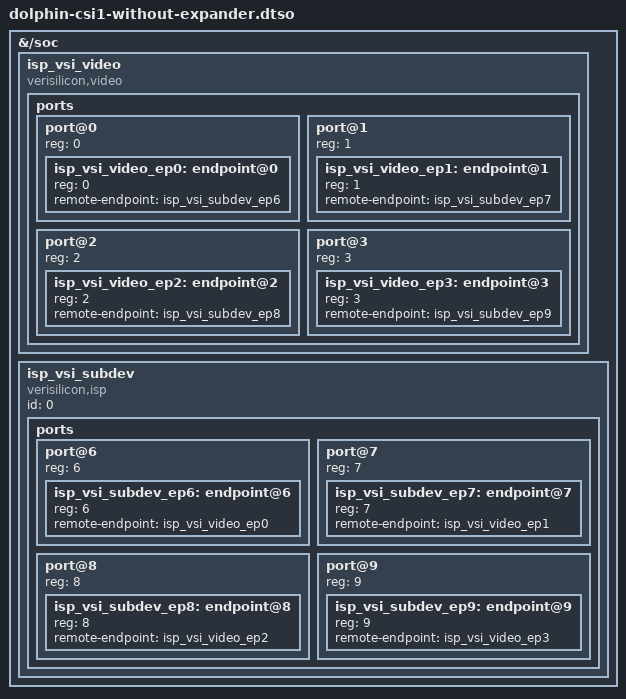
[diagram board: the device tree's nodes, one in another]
#include <dt-bindings/gpio/gpio.h>

/dts-v1/;
/plugin/;


/ {

	fragment@0 {
		target-path = "/soc";
		__overlay__ {
			isp_vsi_video: isp_vsi_video {
				status = "okay";
				compatible = "verisilicon,video";
				ports {
					/delete-property/port@0;
					/delete-property/port@1;
					/delete-property/port@2;
					/delete-property/port@3;
					#address-cells = <1>;
					#size-cells = <0>;
					port@0 {
						reg = <0>;
						#address-cells = <1>;
						#size-cells = <0>;
						isp_vsi_video_ep0: endpoint@0 {
							reg = <0>;
							remote-endpoint = <&isp_vsi_subdev_ep6>;
						};
					};
					port@1 {
						reg = <1>;
						#address-cells = <1>;
						#size-cells = <0>;
						isp_vsi_video_ep1: endpoint@1 {
							reg = <1>;
							remote-endpoint = <&isp_vsi_subdev_ep7>;
						};
					};
					port@2 {
						reg = <2>;
						#address-cells = <1>;
						#size-cells = <0>;
						isp_vsi_video_ep2: endpoint@2 {
							reg = <2>;
							remote-endpoint = <&isp_vsi_subdev_ep8>;
						};
					};
					port@3 {
						reg = <3>;
						#address-cells = <1>;
						#size-cells = <0>;
						isp_vsi_video_ep3: endpoint@3 {
							reg = <3>;
							remote-endpoint = <&isp_vsi_subdev_ep9>;
						};
					};
				};
			};
        	};
	};

	fragment@1 {
		target-path = "/soc";
		__overlay__ {
			isp_vsi_subdev: isp_vsi_subdev {
				id = <0>;
				status = "okay";
				compatible = "verisilicon,isp";
				ports {
					#address-cells = <1>;
					#size-cells = <0>;
					/delete-property/port@1;
					/delete-property/port@2;
					/delete-property/port@3;
					/delete-property/port@4;
					port@6 {
						reg = <6>;
						#address-cells = <1>;
						#size-cells = <0>;
						isp_vsi_subdev_ep6: endpoint@6 {
							reg = <6>;
							remote-endpoint = <&isp_vsi_video_ep0>;
						};
					};
					port@7 {
						reg = <7>;
						#address-cells = <1>;
						#size-cells = <0>;
						isp_vsi_subdev_ep7: endpoint@7 {
							reg = <7>;
							remote-endpoint = <&isp_vsi_video_ep1>;
						};
					};
					port@8 {
						reg = <8>;
						#address-cells = <1>;
						#size-cells = <0>;
						isp_vsi_subdev_ep8: endpoint@8 {
							reg = <8>;
							remote-endpoint = <&isp_vsi_video_ep2>;
						};
					};
					port@9 {
						reg = <9>;
						#address-cells = <1>;
						#size-cells = <0>;
						isp_vsi_subdev_ep9: endpoint@9 {
							reg = <9>;
							remote-endpoint = <&isp_vsi_video_ep3>;
						};
					};
				};
        		};
		};
	};
};
